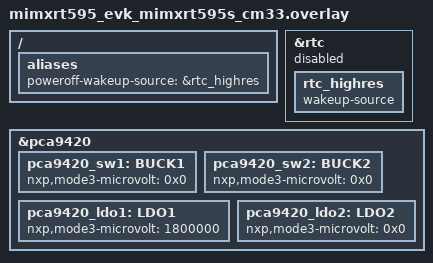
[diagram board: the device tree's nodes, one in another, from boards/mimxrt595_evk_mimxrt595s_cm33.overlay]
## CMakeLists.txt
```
# Copyright 2025 NXP
# SPDX-License-Identifier: Apache-2.0

cmake_minimum_required(VERSION 3.20.0)
find_package(Zephyr REQUIRED HINTS $ENV{ZEPHYR_BASE})
project(nxp_mcu_poweroff)

target_sources_ifdef(CONFIG_POWEROFF_COUNTER_WAKEUP app PRIVATE src/counter_wakeup.c)
target_sources_ifdef(CONFIG_POWEROFF_BUTTON_WAKEUP app PRIVATE src/button_wakeup.c)
```

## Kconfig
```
# Copyright 2025 NXP
# SPDX-License-Identifier: Apache-2.0

mainmenu "NXP MCU POWER OFF DEMO"

choice NXP_MCU_POWEROFF_WAKEUP_SOURCE
	prompt "Select the wakeup source for poweroff"

	config POWEROFF_COUNTER_WAKEUP
		bool "Counter wakeup"
		select COUNTER
		depends on BOARD_FRDM_MCXA153 || BOARD_FRDM_MCXA156 ||	\
				BOARD_FRDM_MCXA346 || BOARD_FRDM_MCXA266 ||	\
				BOARD_FRDM_MCXN947 || BOARD_MIMXRT595_EVK
		help
		  Use counter to wake up device from poweroff.
		  Selected by default for compatible boards.

	config POWEROFF_BUTTON_WAKEUP
		bool "Button wakeup"
		select GPIO
		depends on BOARD_FRDM_MCXN236
		help
		  Use on-board wakeup button to wake up device
		  from poweroff.
		  Selected by default for compatible boards.

endchoice

source "Kconfig.zephyr"
```

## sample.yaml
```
# Copyright 2025 NXP
# SPDX-License-Identifier: Apache-2.0

sample:
  name: Poweroff example for NXP MCUs
common:
  tags: power
tests:
  sample.boards.nxp.mcu.poweroff:
    platform_allow:
      - frdm_mcxa156
      - frdm_mcxa153
      - frdm_mcxa346
      - frdm_mcxa266
      - frdm_mcxn236/mcxn236
      - frdm_mcxn947/mcxn947/cpu0
      - mimxrt595_evk/mimxrt595s/cm33
  sample.boards.nxp.mcu.poweroff.counter_wakeup:
    platform_allow:
      - frdm_mcxa156
      - frdm_mcxa153
      - frdm_mcxa346
      - frdm_mcxa266
      - frdm_mcxn947/mcxn947/cpu0
      - mimxrt595_evk/mimxrt595s/cm33
    harness: console
    harness_config:
      type: multi_line
      ordered: true
      regex:
        - "Press 'enter' key to power off the system"
        - "Will wakeup after 5 seconds"
        - "Powering off"
  sample.boards.nxp.mcu.poweroff.button_wakeup:
    platform_allow:
      - frdm_mcxn236/mcxn236
    harness: console
    harness_config:
      type: multi_line
      ordered: true
      regex:
        - "Press 'enter' key to power off the system"
        - "Will wakeup after press wakeup button"
        - "Powering off"
```

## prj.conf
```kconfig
# Copyright 2025 NXP
# SPDX-License-Identifier: Apache-2.0

CONFIG_POWEROFF=y
CONFIG_CONSOLE_SUBSYS=y
CONFIG_CONSOLE_GETCHAR=y
```

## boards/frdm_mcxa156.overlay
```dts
/*
 * Copyright 2025 NXP
 *
 * SPDX-License-Identifier: Apache-2.0
 */

/ {
	aliases {
		poweroff-wakeup-source = &lptmr0;
	};
};

&lptmr0 {
	status = "okay";
	timer-mode-sel = <0>;
	clk-source = <1>;
	clock-frequency = <16384>;
	resolution = <32>;
	wakeup-source;
};
```

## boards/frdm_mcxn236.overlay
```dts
/*
 * Copyright 2025 NXP
 *
 * SPDX-License-Identifier: Apache-2.0
 */

#include <zephyr/dt-bindings/gpio/nxp-kinetis-gpio.h>

/ {
	aliases {
		poweroff-wakeup-source = &user_button_2;
	};
};

&gpio0 {
	wakeup-source;
	wakeup-line = <KINETIS_GPIO_20_FALLING_EDGE>;
};
```

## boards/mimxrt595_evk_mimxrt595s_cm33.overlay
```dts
/*
 * Copyright 2022, 2025 NXP
 *
 * SPDX-License-Identifier: Apache-2.0
 */

/ {
	aliases {
		poweroff-wakeup-source = &rtc_highres;
	};
};

&rtc {
	status = "disabled";
	rtc_highres: rtc_highres {
		status = "okay";
		wakeup-source;
	};
};

/* MIMXRT595 poweroff corresponds to its full deep power down mode.
 * In this mode, external supplies are powered off except for VDD_AO1V8.
 * VDD_CORE (PMIC SW1 output), VDD1V8 (PMIC SW2 output), VDD_IO (PMIC LDO2 output)
 * need to be turned off.
 */
&pca9420 {
	pca9420_sw1: BUCK1 {
		nxp,mode3-microvolt = < 0x0 >;
	};

	pca9420_sw2: BUCK2 {
		nxp,mode3-microvolt = < 0x0 >;
	};

	pca9420_ldo1: LDO1 {
		nxp,mode3-microvolt = < 1800000 >;
	};

	pca9420_ldo2: LDO2 {
		nxp,mode3-microvolt = < 0x0 >;
	};
};
```

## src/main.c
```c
/*
 * Copyright 2025 NXP
 *
 * SPDX-License-Identifier: Apache-2.0
 */

#include <stdio.h>
#include <zephyr/sys/poweroff.h>
#include <zephyr/sys_clock.h>
#include <zephyr/console/console.h>

#if defined(CONFIG_COUNTER_WAKEUP_ENABLE)
#include <zephyr/drivers/counter.h>
#endif

#if defined(CONFIG_GPIO_WAKEUP_ENABLE)
#include <zephyr/drivers/gpio.h>
#endif

int main(void)
{
	int ret;

#if defined(CONFIG_COUNTER_WAKEUP_ENABLE)
	const struct device *dev = DEVICE_DT_GET(DT_ALIAS(poweroff_wakeup_source));

	struct counter_top_cfg top_cfg = {
		.ticks = counter_us_to_ticks(dev, 5 * USEC_PER_SEC),
		.callback = NULL,
		.user_data = NULL,
		.flags = 0,
	};

	if (!device_is_ready(dev)) {
		printf("Wakeup counter device not ready\n");
		return 0;
	}

	ret = counter_set_top_value(dev, &top_cfg);

	if (ret < 0) {
		printf("Could not set wakeup counter value (%d)\n", ret);
		return 0;
	}

	ret = counter_start(dev);
	if (ret < 0) {
		printf("Could not start wakeup counter (%d)\n", ret);
		return 0;
	}

	console_init();
	printf("Press 'enter' key to power off the system\n");
	console_getchar();
	printf("Will wakeup after 5 seconds\n");
#endif

#if defined(CONFIG_GPIO_WAKEUP_ENABLE)
	const struct gpio_dt_spec wakeup_button =
		GPIO_DT_SPEC_GET(DT_ALIAS(poweroff_wakeup_source), gpios);

	ret = gpio_pin_configure_dt(&wakeup_button, GPIO_INPUT);
	if (ret < 0) {
		printf("Could not configure wakeup GPIO (%d)\n", ret);
		return 0;
	}

	ret = gpio_pin_interrupt_configure_dt(&wakeup_button, GPIO_INT_LEVEL_ACTIVE);
	if (ret < 0) {
		printf("Could not configure wakeup GPIO interrupt (%d)\n", ret);
		return 0;
	}

	console_init();
	printf("Press 'enter' key to power off the system\n");
	console_getchar();
	printf("Will wakeup after press wakeup button\n");
#endif

	printf("Powering off\n");

	sys_poweroff();

	return 0;
}
```

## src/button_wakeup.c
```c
/*
 * Copyright 2025 NXP
 *
 * SPDX-License-Identifier: Apache-2.0
 */

#include <stdio.h>
#include <zephyr/sys/poweroff.h>
#include <zephyr/sys_clock.h>
#include <zephyr/console/console.h>
#include <zephyr/drivers/gpio.h>

int main(void)
{
	int ret;

	const struct gpio_dt_spec wakeup_button =
		GPIO_DT_SPEC_GET(DT_ALIAS(poweroff_wakeup_source), gpios);

	ret = gpio_pin_configure_dt(&wakeup_button, GPIO_INPUT);
	if (ret < 0) {
		printf("Could not configure wakeup GPIO (%d)\n", ret);
		return 0;
	}

	ret = gpio_pin_interrupt_configure_dt(&wakeup_button, GPIO_INT_LEVEL_ACTIVE);
	if (ret < 0) {
		printf("Could not configure wakeup GPIO interrupt (%d)\n", ret);
		return 0;
	}

	console_init();
	printf("Press 'enter' key to power off the system\n");
	console_getchar();
	printf("Will wakeup after press wakeup button\n");

	printf("Powering off\n");

	sys_poweroff();

	return 0;
}
```

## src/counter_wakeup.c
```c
/*
 * Copyright 2025 NXP
 *
 * SPDX-License-Identifier: Apache-2.0
 */

#include <stdio.h>
#include <zephyr/sys/poweroff.h>
#include <zephyr/sys_clock.h>
#include <zephyr/console/console.h>
#include <zephyr/drivers/counter.h>

int main(void)
{
	int ret;

	const struct device *dev = DEVICE_DT_GET(DT_ALIAS(poweroff_wakeup_source));

	struct counter_top_cfg top_cfg = {
		.ticks = counter_us_to_ticks(dev, 5 * USEC_PER_SEC),
		.callback = NULL,
		.user_data = NULL,
		.flags = 0,
	};

	if (!device_is_ready(dev)) {
		printf("Wakeup counter device not ready\n");
		return 0;
	}

	ret = counter_set_top_value(dev, &top_cfg);

	if (ret < 0) {
		printf("Could not set wakeup counter value (%d)\n", ret);
		return 0;
	}

	ret = counter_start(dev);
	if (ret < 0) {
		printf("Could not start wakeup counter (%d)\n", ret);
		return 0;
	}

	console_init();
	printf("Press 'enter' key to power off the system\n");
	console_getchar();
	printf("Will wakeup after 5 seconds\n");

	printf("Powering off\n");

	sys_poweroff();

	return 0;
}
```
